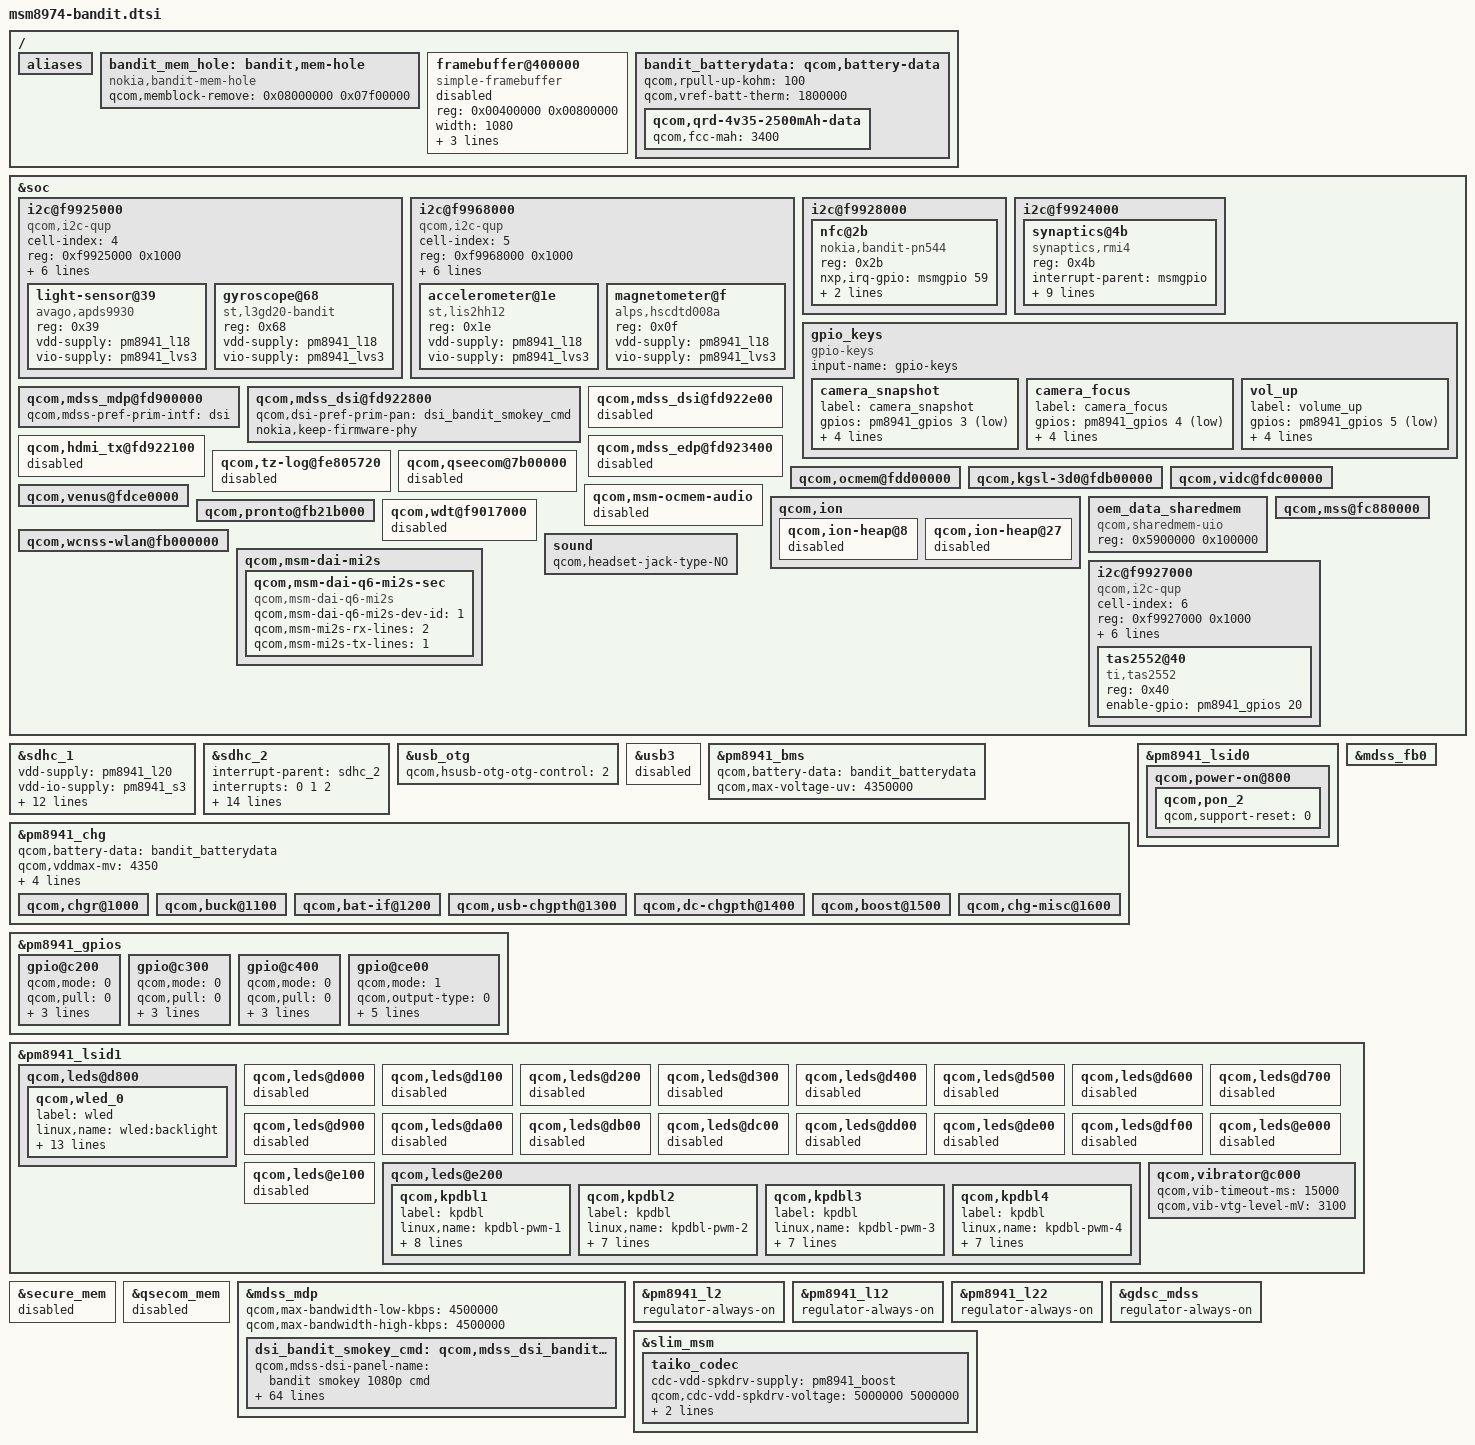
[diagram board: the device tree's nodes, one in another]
/*
 * Nokia Lumia 1520 (bandit), board description for the Android 3.4 kernel.
 *
 * Copyright (c) 2013, The Linux Foundation. All rights reserved.
 * Copyright (c) 2026, Lorenzo Giannoccaro.
 *
 * This program is free software; you can redistribute it and/or modify
 * it under the terms of the GNU General Public License version 2 and
 * only version 2 as published by the Free Software Foundation.
 *
 * Hardware facts (touch wiring, buttons, framebuffer, regulators) come from
 * the mainline bring-up by KorelisLabs (lumia-1520-mainline) and the stock
 * ACPI tables; the PMIC/USB/eMMC setup follows the Qualcomm MTP, which the
 * 1520 board closely matches.
 *
 * The phone boots through the Windows Phone firmware: Nokia UEFI ->
 * bootmgr -> BootShim -> lk1st. Its TrustZone does not implement several
 * SCM calls used by Android kernels; see arch/arm/mach-msm/tz-restricted.c.
 */

/ {
	aliases {
		/* No user-accessible UART on the 1520 */
	};

	/*
	 * The kernel runs with PHYS_OFFSET 0x10000000 (lk1st loads it at
	 * 0x10008000), so RAM below 256 MB is not used: it holds the UEFI
	 * framebuffer (0x00400000), the CPU parking mailboxes (0x00300000)
	 * and the firmware carve-outs. The carve-outs are listed here as well
	 * (modem, mba, wcnss, adsp, venus, smem, tz, rfsa, rmtfs; same map as
	 * mainline qcom-msm8974.dtsi, verified on the 1520 by the mainline
	 * port) so they stay out of the memory map if PHYS_OFFSET changes.
	 */
	bandit_mem_hole: bandit,mem-hole {
		compatible = "nokia,bandit-mem-hole";
		qcom,memblock-remove = <0x08000000 0x07f00000>;
	};

	/*
	 * Buffer left running by the UEFI (1080x1920, 32 bpp, address read
	 * from the MDP RGB0 pipe by the mainline port). Kept as a fallback
	 * console without touching the display hardware: enable it and
	 * disable MDSS below for a software-only display.
	 */
	framebuffer@400000 {
		compatible = "simple-framebuffer";
		status = "disabled";	/* the panel is driven by MDSS */
		reg = <0x00400000 0x00800000>;
		width = <1080>;
		height = <1920>;
		stride = <4320>;
		format = "a8b8g8r8";	/* RGB0 set to R,G,B,A by bandit-splash.c */
	};
};

&soc {
	/*
	 * Sensor buses, as found by I2C scans in the lumia-1520-mainline port:
	 * BLSP1 QUP3 (APDS-9930 ambient light/proximity at 0x39, another part
	 * at 0x68) and BLSP2 QUP6 (two parts at 0x0f and 0x1e). On Windows the
	 * stock qcSensors driver hands the BLSP2 parts to the ADSP. All the
 * sensors are powered from PM8941 L18 (VDD) and LVS3 (VIO), as the stock
 * ACPI PEP configuration votes them.
	 */
	i2c@f9925000 { /* BLSP1 QUP3 */
		cell-index = <4>;
		compatible = "qcom,i2c-qup";
		reg = <0xf9925000 0x1000>;
		#address-cells = <1>;
		#size-cells = <0>;
		reg-names = "qup_phys_addr";
		interrupts = <0 97 0>;
		interrupt-names = "qup_err_intr";
		qcom,i2c-bus-freq = <100000>;
		qcom,i2c-src-freq = <19200000>;
		qcom,master-id = <86>;
		qcom,scl-gpio = <&msmgpio 11 0>;
		qcom,sda-gpio = <&msmgpio 10 0>;

		/* \_SB.APS1 (QPDS_APS): interrupt on TLMM GPIO 74, polled for now */
		light-sensor@39 {
			compatible = "avago,apds9930";
			reg = <0x39>;
			vdd-supply = <&pm8941_l18>;
			vio-supply = <&pm8941_lvs3>;
		};

		/*
		 * \_SB.GYR1 (L3GD20S): ST L3GD20-compatible, WHO_AM_I reads 0x00.
		 * Interrupts on TLMM GPIO 66 and 68, polled for now.
		 */
		gyroscope@68 {
			compatible = "st,l3gd20-bandit";
			reg = <0x68>;
			vdd-supply = <&pm8941_l18>;
			vio-supply = <&pm8941_lvs3>;
		};
	};

	i2c@f9968000 { /* BLSP2 QUP6 */
		cell-index = <5>;
		compatible = "qcom,i2c-qup";
		reg = <0xf9968000 0x1000>;
		#address-cells = <1>;
		#size-cells = <0>;
		reg-names = "qup_phys_addr";
		interrupts = <0 106 0>;
		interrupt-names = "qup_err_intr";
		qcom,i2c-bus-freq = <100000>;
		qcom,i2c-src-freq = <19200000>;
		qcom,master-id = <84>;
		qcom,scl-gpio = <&msmgpio 88 0>;
		qcom,sda-gpio = <&msmgpio 87 0>;

		/* Parts of \_SB.SEN1 (QCOM2495), run by the ADSP on Windows */
		accelerometer@1e {
			compatible = "st,lis2hh12";
			reg = <0x1e>;
			vdd-supply = <&pm8941_l18>;
			vio-supply = <&pm8941_lvs3>;
		};

		magnetometer@f {
			compatible = "alps,hscdtd008a";
			reg = <0x0f>;
			vdd-supply = <&pm8941_l18>;
			vio-supply = <&pm8941_lvs3>;
		};
	};

	/*
	 * NFC (\_SB.NFC1, NXP_NFCC): NXP PN544 (HCI/LLC) on BLSP1 QUP6. VEN is
	 * TLMM 57 (the chip answers only while it is high), the firmware
	 * download line TLMM 85, the interrupt TLMM 59. Supply is S3, always
	 * on; the reference clock is BBCLK2 (ref_clk lookup on 3-002b).
	 */
	i2c@f9928000 { /* BLSP1 QUP6 */
		nfc@2b {
			compatible = "nokia,bandit-pn544";
			reg = <0x2b>;
			nxp,irq-gpio = <&msmgpio 59 0>;
			nxp,ven-gpio = <&msmgpio 57 0>;
			nxp,firm-gpio = <&msmgpio 85 0>;
		};
	};

	/* Touchscreen: Synaptics PLG0175-02 (RMI4), from the stock DSDT */
	i2c@f9924000 {
		synaptics@4b {
			compatible = "synaptics,rmi4";
			reg = <0x4b>;
			interrupt-parent = <&msmgpio>;
			interrupts = <61 0x2008>;
			vdd-supply = <&pm8941_l22>;
			vcc_i2c-supply = <&pm8941_l6>;
			synaptics,reset-gpio = <&msmgpio 60 0x00>;
			synaptics,irq-gpio = <&msmgpio 61 0x2008>;
			/*
			 * No display-coords: this driver reports raw sensor
			 * coordinates, so the axes must use the sensor range
			 * read from F11/F12 (Android scales it to the panel).
			 */
			synaptics,i2c-pull-up;
			/*
			 * Capacitive keys below the panel (F1A 0D buttons):
			 * back, start, search on Windows. The driver keeps
			 * 8-bit codes, so search is sent as KEY_MENU and the
			 * key layout makes it app switch. The 0dbutton sysfs
			 * attribute turns them off for the navigation bar.
			 */
			synaptics,button-map = <158 172 139>;
			/*
			 * Double tap timing of the Windows touch settings
			 * (bandit_SynapticsTouch.inf: DoubleTapMaxTapTime10ms
			 * 0x23, DoubleTapMaxTapDistance100um 0x1e), written to
			 * F12 ctrl18 at screen off. The 5 x 5 mm dead zone has
			 * no known register.
			 */
			synaptics,dtap-max-time = <35>;
			synaptics,dtap-max-dist = <30>;
		};
	};

	gpio_keys {
		compatible = "gpio-keys";
		input-name = "gpio-keys";

		camera_snapshot {
			label = "camera_snapshot";
			gpios = <&pm8941_gpios 3 0x1>;
			linux,input-type = <1>;
			linux,code = <0x2fe>;
			gpio-key,wakeup;
			debounce-interval = <15>;
		};

		camera_focus {
			label = "camera_focus";
			gpios = <&pm8941_gpios 4 0x1>;
			linux,input-type = <1>;
			linux,code = <0x210>;
			gpio-key,wakeup;
			debounce-interval = <15>;
		};

		vol_up {
			label = "volume_up";
			gpios = <&pm8941_gpios 5 0x1>;
			linux,input-type = <1>;
			linux,code = <115>;
			gpio-key,wakeup;
			debounce-interval = <15>;
		};
	};

	/*
	 * Display: MDSS continuous splash on the command mode panel the
	 * UEFI leaves on. No reset/enable lines (the MTP ones are not the
	 * 1520's) and no power-on commands: Windows sends none either.
	 */
	qcom,mdss_mdp@fd900000 {
		qcom,mdss-pref-prim-intf = "dsi";
	};
	qcom,mdss_dsi@fd922800 {
		qcom,dsi-pref-prim-pan = <&dsi_bandit_smokey_cmd>;
		/delete-property/ qcom,platform-reset-gpio;
		/delete-property/ qcom,platform-enable-gpio;
		/delete-property/ qcom,platform-te-gpio;
		nokia,keep-firmware-phy;
	};
	qcom,mdss_dsi@fd922e00 {
		status = "disabled";
	};
	qcom,hdmi_tx@fd922100 {
		status = "disabled";
	};
	qcom,mdss_edp@fd923400 {
		status = "disabled";
	};

	/*
	 * Keep off everything that needs TrustZone services the Windows Phone
	 * firmware may not provide (watchdog register save, TZ log, QSEECOM).
	 * Venus (video) is loaded through PAS like the ADSP. OCMEM and the
	 * Adreno 330 work: the OCMEM secure calls are
	 * answered, and kgsl runs without the TZ DCVS governor.
	 */
	qcom,tz-log@fe805720 {
		status = "disabled";
	};
	qcom,qseecom@7b00000 {
		status = "disabled";
	};
	qcom,ocmem@fdd00000 {
		status = "ok";	/* Adreno 330 GMEM */
	};
	qcom,kgsl-3d0@fdb00000 {
		status = "ok";
	};
	qcom,vidc@fdc00000 {
		status = "ok";
	};
	qcom,venus@fdce0000 {
		status = "ok";	/* PAS proc 9: the TZ authenticates it */
	};
};

&sdhc_1 {
	vdd-supply = <&pm8941_l20>;
	vdd-io-supply = <&pm8941_s3>;

	qcom,vdd-always-on;
	qcom,vdd-lpm-sup;
	qcom,vdd-voltage-level = <2950000 2950000>;
	qcom,vdd-current-level = <800 500000>;

	qcom,vdd-io-always-on;
	qcom,vdd-io-voltage-level = <1800000 1800000>;
	qcom,vdd-io-current-level = <250 154000>;

	qcom,pad-pull-on = <0x0 0x3 0x3>;
	qcom,pad-pull-off = <0x0 0x3 0x3>;
	qcom,pad-drv-on = <0x7 0x4 0x4>;
	qcom,pad-drv-off = <0x0 0x0 0x0>;

	qcom,nonremovable;
	status = "ok";
};

/*
 * microSD, wired as on the MTP: the stock DSDT gives SDC2 card detect on
 * TLMM GPIO 62 and powers it from PM8941 L21 (card) and L13 (I/O).
 */
&sdhc_2 {
	#address-cells = <0>;
	interrupt-parent = <&sdhc_2>;
	interrupts = <0 1 2>;
	#interrupt-cells = <1>;
	interrupt-map-mask = <0xffffffff>;
	interrupt-map = <0 &intc 0 125 0
			1 &intc 0 221 0
			2 &msmgpio 62 0x3>;
	interrupt-names = "hc_irq", "pwr_irq", "status_irq";
	cd-gpios = <&msmgpio 62 0x1>;

	vdd-supply = <&pm8941_l21>;
	vdd-io-supply = <&pm8941_l13>;

	qcom,vdd-voltage-level = <2950000 2950000>;
	qcom,vdd-current-level = <9000 800000>;

	qcom,vdd-io-voltage-level = <1800000 2950000>;
	qcom,vdd-io-current-level = <6 22000>;

	qcom,pad-pull-on = <0x0 0x3 0x3>; /* no-pull, pull-up, pull-up */
	qcom,pad-pull-off = <0x0 0x3 0x3>;
	qcom,pad-drv-on = <0x4 0x4 0x4>; /* 10mA */
	qcom,pad-drv-off = <0x0 0x0 0x0>;
	status = "ok";
};

/*
 * The micro-USB port is wired to the USB 2.0 controller at f9a55000 (the
 * mainline port drives it as ci_hdrc), not to the USB 3.0 core used by the
 * MTP. VBUS detection through the PM8941 charger.
 */
&usb_otg {
	status = "ok";
	qcom,hsusb-otg-otg-control = <2>;
};

&usb3 {
	status = "disabled";
};

/ {
	bandit_batterydata: qcom,battery-data {
		qcom,rpull-up-kohm = <100>;
		qcom,vref-batt-therm = <1800000>;

		/*
		 * No BV-4BW profile is available: use the 4.35 V reference
		 * profile (OCV curve of a high voltage cell) with the BV-4BW
		 * capacity, 3400 mAh at 4.35 V.
		 */
		/include/ "../batterydata-qrd-4v35-2500mah.dtsi"
	};
};

&bandit_batterydata {
	qcom,qrd-4v35-2500mAh-data {
		qcom,fcc-mah = <3400>;
	};
};

&pm8941_bms {
	status = "ok";
	qcom,battery-data = <&bandit_batterydata>;
	qcom,max-voltage-uv = <4350000>;
};

/*
 * Charging for the BV-4BW (3400 mAh, Li-ion, 4.35 V maximum): charge to
 * 4.35 V (minimum input 4.47 V as on the 4.35 V reference boards; the
 * VDD_SAFE ceiling is write-once and the UEFI leaves it at 4.40 V), 4.10 V below 10 C and above 45 C (battery thermistor through
 * the BMS). Fast charge limited to 1 A for margin, so the safety timer is
 * raised from 150 to 330 minutes, enough for the full 3400 mAh.
 */
&pm8941_chg {
	status = "ok";
	qcom,battery-data = <&bandit_batterydata>;
	qcom,vddmax-mv = <4350>;
	qcom,vinmin-mv = <4470>;
	qcom,ibatmax-ma = <1000>;
	qcom,ibatsafe-ma = <1000>;
	qcom,tchg-mins = <330>;

	qcom,chgr@1000 {
		status = "ok";
	};
	qcom,buck@1100 {
		status = "ok";
	};
	qcom,bat-if@1200 {
		status = "ok";
	};
	qcom,usb-chgpth@1300 {
		status = "ok";
	};
	qcom,dc-chgpth@1400 {
		status = "ok";
	};
	qcom,boost@1500 {
		status = "ok";
	};
	qcom,chg-misc@1600 {
		status = "ok";
	};
};

&pm8941_gpios {
	gpio@c200 { /* GPIO 3: camera snapshot */
		qcom,mode = <0>;
		qcom,pull = <0>;
		qcom,vin-sel = <2>;
		qcom,src-sel = <0>;
		qcom,master-en = <1>;
	};

	gpio@c300 { /* GPIO 4: camera focus */
		qcom,mode = <0>;
		qcom,pull = <0>;
		qcom,vin-sel = <2>;
		qcom,src-sel = <0>;
		qcom,master-en = <1>;
	};

	gpio@c400 { /* GPIO 5: volume up */
		qcom,mode = <0>;
		qcom,pull = <0>;
		qcom,vin-sel = <2>;
		qcom,src-sel = <0>;
		qcom,master-en = <1>;
	};
};

/* Volume down (RESIN): key only, no PMIC reset on a long press */
&pm8941_lsid0 {
	qcom,power-on@800 {
		qcom,pon_2 {
			qcom,support-reset = <0>;
		};
	};
};

/*
 * The MTP/OnePlus splash carve-out (0x03200000) lies below PHYS_OFFSET on
 * the 1520 (the kernel runs from 0x10000000) and is not the UEFI
 * framebuffer (0x00400000): reserving it made bootmem BUG() in paging_init.
 */
&mdss_fb0 {
	/delete-property/ qcom,memblock-reserve;
};

/*
 * LEDs: msm-pm8941.dtsi declares the qcom,leds-qpnp peripherals without
 * child nodes, so every probe fails with -ECHILD. The 1520 has no RGB or
 * PM8941 flash (its flash is an external part on TLMM GPIO 83/84, stock
 * DSDT QCOM0705) and the keypad backlight is not identified yet: switch
 * them off. The WLED (leds@d800) drives the LCD backlight: configured
 * below with the values the UEFI programs.
 */
&pm8941_lsid1 {
	/*
	 * LCD backlight, as the UEFI leaves the PM8941 WLED (registers read
	 * on an RM-937): 2 strings (CURR_SINK 0x60), 12 mA full scale each,
	 * OVP 27 V (0x03), boost limit 0x02, switching frequency 0x0B,
	 * output feedback 0, high pole capacitance 0, internal modulator.
	 * MDSS drives it through "bkl-trigger" (panel bl_ctrl_wled).
	 */
	qcom,leds@d800 {
		status = "okay";
		qcom,wled_0 {
			label = "wled";
			linux,name = "wled:backlight";
			linux,default-trigger = "bkl-trigger";
			qcom,id = <0>;
			qcom,default-state = "on";
			qcom,max-current = <12>;
			qcom,num-strings = <2>;
			qcom,cs-out-en;
			/* the UEFI leaves the panel CABC PWM scaling the strings */
			qcom,cabc-disable;
			qcom,ovp-val = <3>;
			qcom,boost-curr-lim = <2>;
			qcom,switch-freq = <11>;
			qcom,op-fdbck = <0>;
			qcom,cp-sel = <0>;
			qcom,ctrl-delay-us = <0>;
		};
	};
	qcom,leds@d000 {
		status = "disabled";
	};
	qcom,leds@d100 {
		status = "disabled";
	};
	qcom,leds@d200 {
		status = "disabled";
	};
	qcom,leds@d300 {
		status = "disabled";
	};
	qcom,leds@d400 {
		status = "disabled";
	};
	qcom,leds@d500 {
		status = "disabled";
	};
	qcom,leds@d600 {
		status = "disabled";
	};
	qcom,leds@d700 {
		status = "disabled";
	};
	qcom,leds@d900 {
		status = "disabled";
	};
	qcom,leds@da00 {
		status = "disabled";
	};
	qcom,leds@db00 {
		status = "disabled";
	};
	qcom,leds@dc00 {
		status = "disabled";
	};
	qcom,leds@dd00 {
		status = "disabled";
	};
	qcom,leds@de00 {
		status = "disabled";
	};
	qcom,leds@df00 {
		status = "disabled";
	};
	qcom,leds@e000 {
		status = "disabled";
	};
	qcom,leds@e100 {
		status = "disabled";
	};
	/*
	 * Capacitive key backlight: the PM8941 keypad backlight (KPDBL) rows,
	 * PWM channels 8-11 as on the MTP. Each row lights part of the keys;
	 * the lights HAL drives all four together.
	 */
	qcom,leds@e200 {
		status = "okay";

		qcom,kpdbl1 {
			label = "kpdbl";
			linux,name = "kpdbl-pwm-1";
			qcom,mode = "pwm";
			qcom,pwm-channel = <8>;
			qcom,pwm-us = <1000>;
			qcom,id = <7>;
			qcom,max-current = <20>;
			qcom,row-id = <0>;
			qcom,row-src-en;
			qcom,always-on;
		};

		qcom,kpdbl2 {
			label = "kpdbl";
			linux,name = "kpdbl-pwm-2";
			qcom,mode = "pwm";
			qcom,pwm-channel = <9>;
			qcom,pwm-us = <1000>;
			qcom,id = <7>;
			qcom,max-current = <20>;
			qcom,row-id = <1>;
			qcom,row-src-en;
		};

		qcom,kpdbl3 {
			label = "kpdbl";
			linux,name = "kpdbl-pwm-3";
			qcom,mode = "pwm";
			qcom,pwm-channel = <10>;
			qcom,pwm-us = <1000>;
			qcom,id = <7>;
			qcom,max-current = <20>;
			qcom,row-id = <2>;
			qcom,row-src-en;
		};

		qcom,kpdbl4 {
			label = "kpdbl";
			linux,name = "kpdbl-pwm-4";
			qcom,mode = "pwm";
			qcom,pwm-channel = <11>;
			qcom,pwm-us = <1000>;
			qcom,id = <7>;
			qcom,max-current = <20>;
			qcom,row-id = <3>;
			qcom,row-src-en;
		};
	};
};

/* OCMEM is disabled above: its audio client would defer forever */
&soc {
	qcom,msm-ocmem-audio {
		status = "disabled";
	};
};

/*
 * Content protection: the Windows Phone TrustZone runs no Android QSEE
 * apps, so the secure (CP_MM) and QSEECOM heaps cannot be used and nothing
 * enabled allocates from them. Dropping their CMA regions returns about
 * 272 MB to normal allocations; ION keeps the system, adsp, audio and PIL
 * heaps.
 */
&secure_mem {
	status = "disabled";
};

&qsecom_mem {
	status = "disabled";
};

&soc {
	qcom,ion {
		qcom,ion-heap@8 {
			status = "disabled";
		};
		qcom,ion-heap@27 {
			status = "disabled";
		};
	};
};

/*
 * rmt_storage (Qualcomm blob from the msm8974 common vendor) refuses to
 * start without an "oem_data" shared memory UIO, an Oppo addition. Give it
 * the same 1 MB window as the Oppo device tree: 0x05900000 is below
 * PHYS_OFFSET on the 1520, so the kernel does not use it, and it stays
 * clear of the PIL region at 0x05d00000.
 */
&soc {
	oem_data_sharedmem {
		compatible = "qcom,sharedmem-uio";
		reg = <0x5900000 0x100000>;
		reg-names = "oem_data";
	};
};

/*
 * Modem: the stock MBA and modem images are SSD encrypted and the TZ
 * decrypts them while PIL loads them (pil-ssd.c). The start is limited by
 * pil_q6v5_mss.max_attempts.
 *
 * WCNSS (Pronto, Wi-Fi/Bluetooth) on, with the 5-wire link to the iris RF
 * chip muxed by the board file. The mainline port saw Pronto never signal
 * ready after PAS, and failed startups end in device resets: watch for
 * reboots when Wi-Fi is turned on.
 */
&soc {
	qcom,mss@fc880000 {
		status = "ok";
	};
	qcom,pronto@fb21b000 {
		status = "ok";
	};
	qcom,wcnss-wlan@fb000000 {
		status = "ok";
	};
};

/*
 * Vibration motor on the PM8941 (stock DSDT VIB1 "NOKIA_VIBRA_PMIC", SPMI
 * SID 1 at 0xC0xx): timed_output/vibrator. Level and timeout as on the
 * Qualcomm reference boards.
 */
&pm8941_lsid1 {
	qcom,vibrator@c000 {
		status = "okay";
		qcom,vib-timeout-ms = <15000>;
		qcom,vib-vtg-level-mV = <3100>;
	};
};

/*
 * APSS watchdog: kept off. Enabling the driver (560ac391) froze the boot at
 * the watchdog probe and the SoC reset about 10 s later, in a loop: the
 * Windows Phone firmware does not let Linux program it this way. Why the
 * system still resets about 10 minutes after boot is open.
 */
&soc {
	qcom,wdt@f9017000 {
		status = "disabled";
	};
};

/*
 * Panel "Smokey" (stock ACPI panel XML): 1080x1920, 24 bpp, DSI 4 lanes,
 * command mode, 60 Hz. Bit clock 859.8 Mbps per lane as left by the UEFI
 * (byte0 107480566 Hz, pclk0 143307421 Hz); porches chosen so that
 * htotal x vtotal x 60 matches pclk0, vtotal 1925 as the UEFI pingpong.
 * The PHY is kept as programmed by the firmware (nokia,keep-firmware-phy),
 * so the PHY timings below are not written to the hardware.
 */
&mdss_mdp {
	/*
	 * Same as the Lumia 930: with the msm8974 defaults (2.3 GB/s video,
	 * 3.0 GB/s command mode) the overlay check rejects the notification
	 * shade over the launcher (4.3 GB/s with the 2x fudge factor) and
	 * SurfaceFlinger composes it on the busy GPU. Measured on the 930
	 * (video mode): all layers on MDP pipes, no underrun.
	 */
	qcom,max-bandwidth-low-kbps = <4500000>;
	qcom,max-bandwidth-high-kbps = <4500000>;

	dsi_bandit_smokey_cmd: qcom,mdss_dsi_bandit_smokey_cmd {
		qcom,mdss-dsi-panel-name = "bandit smokey 1080p cmd";
		qcom,mdss-dsi-panel-controller = <&mdss_dsi0>;
		qcom,mdss-dsi-panel-type = "dsi_cmd_mode";
		qcom,mdss-dsi-panel-destination = "display_1";
		qcom,cont-splash-enabled;
		qcom,mdss-dsi-panel-framerate = <60>;
		qcom,mdss-dsi-panel-clockrate = <859844528>;
		qcom,mdss-dsi-virtual-channel-id = <0>;
		qcom,mdss-dsi-stream = <0>;
		qcom,mdss-dsi-panel-width = <1080>;
		qcom,mdss-dsi-panel-height = <1920>;
		qcom,mdss-pan-physical-width-dimension = <75>;
		qcom,mdss-pan-physical-height-dimension = <132>;
		qcom,mdss-dsi-h-front-porch = <100>;
		qcom,mdss-dsi-h-back-porch = <41>;
		qcom,mdss-dsi-h-pulse-width = <20>;
		qcom,mdss-dsi-h-sync-skew = <0>;
		qcom,mdss-dsi-v-front-porch = <2>;
		qcom,mdss-dsi-v-back-porch = <2>;
		qcom,mdss-dsi-v-pulse-width = <1>;
		qcom,mdss-dsi-h-left-border = <0>;
		qcom,mdss-dsi-h-right-border = <0>;
		qcom,mdss-dsi-v-top-border = <0>;
		qcom,mdss-dsi-v-bottom-border = <0>;
		qcom,mdss-dsi-bpp = <24>;
		qcom,mdss-dsi-color-order = "rgb_swap_rgb";
		qcom,mdss-dsi-underflow-color = <0xff>;
		qcom,mdss-dsi-border-color = <0>;
		qcom,mdss-dsi-lane-0-state;
		qcom,mdss-dsi-lane-1-state;
		qcom,mdss-dsi-lane-2-state;
		qcom,mdss-dsi-lane-3-state;
		qcom,mdss-dsi-lane-map = "lane_map_0123";
		qcom,mdss-dsi-t-clk-post = <0x1e>;
		qcom,mdss-dsi-t-clk-pre = <0x33>;
		qcom,mdss-dsi-panel-timings = [e6 38 26 00 68 aa 2a 3a 2c 03 04 00];
		qcom,mdss-dsi-wr-mem-start = <0x2c>;
		qcom,mdss-dsi-wr-mem-continue = <0x3c>;
		qcom,mdss-dsi-te-dcs-command = <1>;
		qcom,mdss-dsi-te-pin-select = <0>;
		/* vsync from the panel TE on MDP_VSYNC_P, as on Windows */
		qcom,mdss-dsi-te-using-te-pin;
		/* send the DCS tear-on (0x35) at unblank so the panel drives TE */
		qcom,mdss-dsi-te-check-enable;
		/*
		 * MADCTL as the stock panel configuration sets it: the UEFI leaves
		 * 0xc0 (frame memory written bottom-up, refreshed top-down: a tear
		 * in the middle of the screen); 0xd4 also reverses the refresh
		 * order, so writes and refresh run the same way.
		 */
		nokia,mdss-dsi-madctl = <0xd4>;
		/*
		 * Screen off/on: display off + sleep in, sleep out + display on,
		 * the DCS part of the (commented out) stock panel sequences. The
		 * panel keeps its rails and is never reset, so its registers
		 * survive sleep; MADCTL is written again before display on. The
		 * first unblank after boot sends nothing (continuous splash).
		 * HS mode, like the tear-on and MADCTL writes that already work
		 * on the PHY left by the UEFI.
		 */
		qcom,mdss-dsi-on-command = [05 01 00 00 78 00 02 11 00
				15 01 00 00 00 00 02 36 d4
				05 01 00 00 14 00 02 29 00];
		qcom,mdss-dsi-off-command = [05 01 00 00 14 00 02 28 00
				05 01 00 00 78 00 02 10 00];
		qcom,mdss-dsi-on-command-state = "dsi_hs_mode";
		qcom,mdss-dsi-off-command-state = "dsi_hs_mode";
		qcom,mdss-dsi-mdp-trigger = "none";
		qcom,mdss-dsi-dma-trigger = "trigger_sw";
		/* tear check on the panel TE: transfers start at the read pointer */
		qcom,mdss-tear-check-sync-cfg-height = <0xfff0>;
		qcom,mdss-tear-check-sync-init-val = <1920>;
		qcom,mdss-tear-check-sync-threshold-start = <4>;
		qcom,mdss-tear-check-sync-threshold-continue = <4>;
		qcom,mdss-tear-check-start-pos = <1920>;
		qcom,mdss-tear-check-rd-ptr-trigger-intr = <1921>;
		qcom,mdss-tear-check-frame-rate = <6000>;
		qcom,mdss-dsi-bl-pmic-control-type = "bl_ctrl_wled";
		qcom,mdss-dsi-bl-min-level = <1>;
		qcom,mdss-dsi-bl-max-level = <4095>;	/* WLED 12-bit */
		/* slightly more saturated colours (LiveDisplay PCC matrix) */
		nokia,mdss-livedisplay-saturation = <115>;
	};
};

/* Panel and DSI PHY rails, MDSS GDSC: never cut (no power-on sequence) */
&pm8941_l2 {
	regulator-always-on;
};
&pm8941_l12 {
	regulator-always-on;
};
&pm8941_l22 {
	regulator-always-on;
};
&gdsc_mdss {
	regulator-always-on;
};

/*
 * Audio: WCD9320 (Taiko) codec on SLIMbus, reset on TLMM 63, interrupt on
 * TLMM 72, as on the MTP. The stock ACPI power state of the codec
 * (\_SB.ADSP.SLM1.ADCM.AUDD, PEP component 0) adds what the MTP gets from
 * msm8974-mtp.dtsi, which this board does not include:
 *  - PM8941 GPIO 15 as a digital output on special function 1 (DIV_CLK1,
 *    the 9.6 MHz codec MCLK), VIN2, high drive strength. Without it the
 *    pin stays an input and the codec never sees MCLK: capture returns
 *    digital silence and MBHC cannot measure.
 *  - component 1: the PM8941 5 V boost at up to 1.5 A, voted only for the
 *    codec's own speaker driver (ACDB devices 67 and 69). It is the Taiko
 *    VDD_SPKDRV supply.
 */
&pm8941_gpios {
	gpio@ce00 { /* GPIO 15: codec MCLK (DIV_CLK1) */
		qcom,mode = <1>;		/* digital output */
		qcom,output-type = <0>;		/* CMOS */
		qcom,pull = <5>;		/* no pull */
		qcom,vin-sel = <2>;		/* VIN2, 1.8 V */
		qcom,out-strength = <3>;	/* high, as on Windows */
		qcom,src-sel = <2>;		/* function 1: DIV_CLK1 */
		qcom,master-en = <1>;
	};
};

/*
 * Headset jack: its insertion switch is normally open. With the default
 * (normally closed) MBHC polarity an empty jack reads as inserted and is
 * classified as a line out, and Android routes all audio there.
 */
&soc {
	sound {
		qcom,headset-jack-type-NO;
	};
};

&slim_msm {
	taiko_codec {
		cdc-vdd-spkdrv-supply = <&pm8941_boost>;
		qcom,cdc-vdd-spkdrv-voltage = <5000000 5000000>;
		qcom,cdc-vdd-spkdrv-current = <1250000>;
		qcom,cdc-on-demand-supplies = "cdc-vdd-spkdrv";
	};
};

/*
 * Loudspeaker: the stock audio routing pairs every speakerphone and
 * ringtone stream with ACDB device 70 (SEC_MI2S_RX) and the feedback with
 * device 74 (SEC_MI2S_TX). The codec power state muxes SCK (TLMM 79), WS
 * (80) and SD1 (82) as outputs and SD0 (81) as an input, so playback leaves
 * on SD1 and the amplifier answers on SD0. The MI2S MCLK pin (78) is used
 * by another device and stays untouched.
 */
&soc {
	qcom,msm-dai-mi2s {
		qcom,msm-dai-q6-mi2s-sec {
			compatible = "qcom,msm-dai-q6-mi2s";
			qcom,msm-dai-q6-mi2s-dev-id = <1>;
			qcom,msm-mi2s-rx-lines = <2>;	/* SD1, TLMM 82 */
			qcom,msm-mi2s-tx-lines = <1>;	/* SD0, TLMM 81 */
		};
	};
};

/*
 * BLSP1 QUP5: stock \_SB.I2C5, whose only client is \_SB.VISA ("Nokia Visa
 * Device") at 0x40 with PM8941 GPIO 20, and which \_SB.ADSP lists as a
 * dependency. No driver is bound yet: the bus is exposed through i2c-dev
 * so the part behind the secondary MI2S can be identified.
 */
&soc {
	i2c@f9927000 { /* BLSP1 QUP5 */
		cell-index = <6>;
		compatible = "qcom,i2c-qup";
		reg = <0xf9927000 0x1000>;
		#address-cells = <1>;
		#size-cells = <0>;
		reg-names = "qup_phys_addr";
		interrupts = <0 99 0>;
		interrupt-names = "qup_err_intr";
		qcom,i2c-bus-freq = <100000>;
		qcom,i2c-src-freq = <19200000>;
		qcom,master-id = <86>;
		qcom,scl-gpio = <&msmgpio 26 0>;
		qcom,sda-gpio = <&msmgpio 25 0>;

		/*
		 * Loudspeaker amplifier (\_SB.VISA): TI TAS2552, identified
		 * by its register map (VER_NUM 0x08). Audio in on the
		 * secondary MI2S (SD1), I/V sense out on SD0, no MCLK: the
		 * PLL runs from BCLK. PM8941 GPIO 20 is its enable
		 * (nSHUTDOWN); the part does not answer while it is low.
		 * VBAT, IOVDD and AVDD have no switchable supply in the stock
		 * tables (no power resource on VISA), so none is listed.
		 */
		tas2552@40 {
			compatible = "ti,tas2552";
			reg = <0x40>;
			enable-gpio = <&pm8941_gpios 20 0>;
		};
	};
};

/*
 * Camera nodes are included by the top level DTS: the real sensor nodes
 * (msm8974-camera-sensor-lumia.dtsi) or, in the camprobe test DTB, the
 * identification probe nodes in their place.
 */
